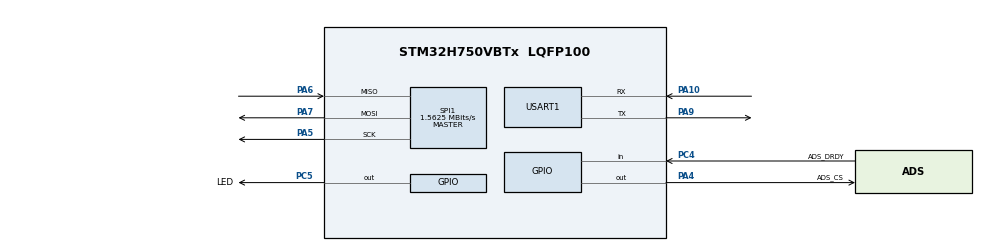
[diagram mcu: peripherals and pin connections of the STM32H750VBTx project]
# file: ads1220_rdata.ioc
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Mcu.Family=STM32H7
Mcu.Name=STM32H750VBTx
Mcu.Package=LQFP100
NVIC.PriorityGroup=NVIC_PRIORITYGROUP_4
NVIC.TIM17_IRQn=true\:15\:0\:false\:false\:true\:false\:true\:true
NVIC.TIM2_IRQn=true\:0\:0\:false\:false\:true\:true\:true\:true
NVIC.TimeBase=TIM17_IRQn
NVIC.TimeBaseIP=TIM17
PA10.Mode=Asynchronous
PA10.Signal=USART1_RX
PA13\ (JTMS/SWDIO).Mode=Serial_Wire
PA13\ (JTMS/SWDIO).Signal=DEBUG_JTMS-SWDIO
PA14\ (JTCK/SWCLK).Mode=Serial_Wire
PA14\ (JTCK/SWCLK).Signal=DEBUG_JTCK-SWCLK
PA4.GPIO_Label=ADS_CS
PA4.GPIO_PuPd=GPIO_PULLUP
PA4.PinState=GPIO_PIN_SET
PA4.Signal=GPIO_Output
PA5.Mode=Full_Duplex_Master
PA5.Signal=SPI1_SCK
PA6.Mode=Full_Duplex_Master
PA6.Signal=SPI1_MISO
PA7.Mode=Full_Duplex_Master
PA7.Signal=SPI1_MOSI
PA9.Mode=Asynchronous
PA9.Signal=USART1_TX
PC4.GPIO_Label=ADS_DRDY
PC4.Signal=GPIO_Input
PC5.GPIO_Label=LED
PC5.Signal=GPIO_Output
PH0-OSC_IN\ (PH0).Mode=HSE-External-Oscillator
PH0-OSC_IN\ (PH0).Signal=RCC_OSC_IN
PH1-OSC_OUT\ (PH1).Mode=HSE-External-Oscillator
PH1-OSC_OUT\ (PH1).Signal=RCC_OSC_OUT
ProjectManager.HeapSize=0x200
ProjectManager.StackSize=0x400
ProjectManager.TargetToolchain=STM32CubeIDE
RCC.ADCFreq_Value=102400000
RCC.APB1Freq_Value=100000000
RCC.APB2Freq_Value=50000000
RCC.APB3Freq_Value=100000000
RCC.APB4Freq_Value=100000000
RCC.CortexFreq_Value=200000000
RCC.D1PPRE=RCC_APB3_DIV2
RCC.D2PPRE1=RCC_APB1_DIV2
RCC.D2PPRE2=RCC_APB2_DIV4
RCC.D3PPRE=RCC_APB4_DIV2
RCC.DIVM1=4
RCC.DIVM2=25
RCC.DIVM3=2
RCC.DIVN1=25
RCC.DIVN2=160
RCC.DIVN3=12
RCC.DIVP2=4
RCC.DIVQ1=4
RCC.DIVQ3=3
RCC.HCLKFreq_Value=200000000
RCC.PLL2FRACN=0
RCC.PLL3FRACN=0
RCC.PLLFRACN=0
RCC.SYSCLKFreq_VALUE=200000000
RCC.SYSCLKSource=RCC_SYSCLKSOURCE_PLLCLK
RCC.USBCLockSelection=RCC_USBCLKSOURCE_PLL3
RCC.USBFreq_Value=128000000
SPI1.BaudRatePrescaler=SPI_BAUDRATEPRESCALER_64
SPI1.CLKPhase=SPI_PHASE_2EDGE
SPI1.CalculateBaudRate=1.5625 MBits/s
SPI1.DataSize=SPI_DATASIZE_8BIT
SPI1.Direction=SPI_DIRECTION_2LINES
SPI1.Mode=SPI_MODE_MASTER
SPI1.VirtualType=VM_MASTER
TIM2.Period=999
TIM2.Prescaler=199
USART1.VirtualMode-Asynchronous=VM_ASYNC
VP_SYS_VS_tim17.Mode=TIM17
VP_TIM2_VS_ClockSourceINT.Mode=Internal
board=custom

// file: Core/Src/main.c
/* USER CODE BEGIN Header */
/**
  ******************************************************************************
  * @file           : main.c
  * @brief          : Main program body
  ******************************************************************************
  * @attention
  *
  * Copyright (c) 2024 STMicroelectronics.
  * All rights reserved.
  *
  * This software is licensed under terms that can be found in the LICENSE file
  * in the root directory of this software component.
  * If no LICENSE file comes with this software, it is provided AS-IS.
  *
  ******************************************************************************
  */
/* USER CODE END Header */
#include "main.h"

/* USER CODE BEGIN Includes */
#include "use.h"
/* USER CODE END Includes */

SPI_HandleTypeDef hspi1;

TIM_HandleTypeDef htim2;

UART_HandleTypeDef huart1;

void SystemClock_Config(void);
static void MX_GPIO_Init(void);
static void MX_SPI1_Init(void);
static void MX_USART1_UART_Init(void);
static void MX_TIM2_Init(void);

/* USER CODE BEGIN 0 */
#ifdef __GNUC__
/* With GCC/RAISONANCE, small printf (option LD Linker->Libraries->Small printf
   set to 'Yes') calls __io_putchar() */
#define PUTCHAR_PROTOTYPE int __io_putchar(int ch)
#else
#define PUTCHAR_PROTOTYPE int fputc(int ch, FILE *f)
#endif /* __GNUC__ */
PUTCHAR_PROTOTYPE
{
  HAL_UART_Transmit(&huart1, (uint8_t *)&ch, 1, 0xFFFF);
  return ch;
}
/* USER CODE END 0 */

int main(void)
{

  /* MCU Configuration--------------------------------------------------------*/

  /* Reset of all peripherals, Initializes the Flash interface and the Systick. */
  HAL_Init();

  /* Configure the system clock */
  SystemClock_Config();

  /* Initialize all configured peripherals */
  MX_GPIO_Init();
  MX_SPI1_Init();
  MX_USART1_UART_Init();
  MX_TIM2_Init();
  /* USER CODE BEGIN 2 */
  setup();
  HAL_TIM_Base_Start_IT(&htim2);
  /* USER CODE END 2 */

  /* Infinite loop */
  while (1)
  {

    /* USER CODE BEGIN 3 */
	  loop();
  }
  /* USER CODE END 3 */
}

void SystemClock_Config(void)
{
  RCC_OscInitTypeDef RCC_OscInitStruct = {0};
  RCC_ClkInitTypeDef RCC_ClkInitStruct = {0};

  /** Supply configuration update enable
  */
  HAL_PWREx_ConfigSupply(PWR_LDO_SUPPLY);

  /** Configure the main internal regulator output voltage
  */
  __HAL_PWR_VOLTAGESCALING_CONFIG(PWR_REGULATOR_VOLTAGE_SCALE3);

  while(!__HAL_PWR_GET_FLAG(PWR_FLAG_VOSRDY)) {}

  /** Initializes the RCC Oscillators according to the specified parameters
  * in the RCC_OscInitTypeDef structure.
  */
  RCC_OscInitStruct.OscillatorType = RCC_OSCILLATORTYPE_HSI;
  RCC_OscInitStruct.HSIState = RCC_HSI_DIV1;
  RCC_OscInitStruct.HSICalibrationValue = RCC_HSICALIBRATION_DEFAULT;
  RCC_OscInitStruct.PLL.PLLState = RCC_PLL_ON;
  RCC_OscInitStruct.PLL.PLLSource = RCC_PLLSOURCE_HSI;
  RCC_OscInitStruct.PLL.PLLM = 4;
  RCC_OscInitStruct.PLL.PLLN = 25;
  RCC_OscInitStruct.PLL.PLLP = 2;
  RCC_OscInitStruct.PLL.PLLQ = 4;
  RCC_OscInitStruct.PLL.PLLR = 2;
  RCC_OscInitStruct.PLL.PLLRGE = RCC_PLL1VCIRANGE_3;
  RCC_OscInitStruct.PLL.PLLVCOSEL = RCC_PLL1VCOWIDE;
  RCC_OscInitStruct.PLL.PLLFRACN = 0;
  if (HAL_RCC_OscConfig(&RCC_OscInitStruct) != HAL_OK)
  {
    Error_Handler();
  }

  /** Initializes the CPU, AHB and APB buses clocks
  */
  RCC_ClkInitStruct.ClockType = RCC_CLOCKTYPE_HCLK|RCC_CLOCKTYPE_SYSCLK
                              |RCC_CLOCKTYPE_PCLK1|RCC_CLOCKTYPE_PCLK2
                              |RCC_CLOCKTYPE_D3PCLK1|RCC_CLOCKTYPE_D1PCLK1;
  RCC_ClkInitStruct.SYSCLKSource = RCC_SYSCLKSOURCE_PLLCLK;
  RCC_ClkInitStruct.SYSCLKDivider = RCC_SYSCLK_DIV1;
  RCC_ClkInitStruct.AHBCLKDivider = RCC_HCLK_DIV1;
  RCC_ClkInitStruct.APB3CLKDivider = RCC_APB3_DIV2;
  RCC_ClkInitStruct.APB1CLKDivider = RCC_APB1_DIV2;
  RCC_ClkInitStruct.APB2CLKDivider = RCC_APB2_DIV4;
  RCC_ClkInitStruct.APB4CLKDivider = RCC_APB4_DIV2;

  if (HAL_RCC_ClockConfig(&RCC_ClkInitStruct, FLASH_LATENCY_4) != HAL_OK)
  {
    Error_Handler();
  }
}

static void MX_SPI1_Init(void)
{

  /* SPI1 parameter configuration*/
  hspi1.Instance = SPI1;
  hspi1.Init.Mode = SPI_MODE_MASTER;
  hspi1.Init.Direction = SPI_DIRECTION_2LINES;
  hspi1.Init.DataSize = SPI_DATASIZE_8BIT;
  hspi1.Init.CLKPolarity = SPI_POLARITY_LOW;
  hspi1.Init.CLKPhase = SPI_PHASE_2EDGE;
  hspi1.Init.NSS = SPI_NSS_SOFT;
  hspi1.Init.BaudRatePrescaler = SPI_BAUDRATEPRESCALER_64;
  hspi1.Init.FirstBit = SPI_FIRSTBIT_MSB;
  hspi1.Init.TIMode = SPI_TIMODE_DISABLE;
  hspi1.Init.CRCCalculation = SPI_CRCCALCULATION_DISABLE;
  hspi1.Init.CRCPolynomial = 0x0;
  hspi1.Init.NSSPMode = SPI_NSS_PULSE_ENABLE;
  hspi1.Init.NSSPolarity = SPI_NSS_POLARITY_LOW;
  hspi1.Init.FifoThreshold = SPI_FIFO_THRESHOLD_01DATA;
  hspi1.Init.TxCRCInitializationPattern = SPI_CRC_INITIALIZATION_ALL_ZERO_PATTERN;
  hspi1.Init.RxCRCInitializationPattern = SPI_CRC_INITIALIZATION_ALL_ZERO_PATTERN;
  hspi1.Init.MasterSSIdleness = SPI_MASTER_SS_IDLENESS_00CYCLE;
  hspi1.Init.MasterInterDataIdleness = SPI_MASTER_INTERDATA_IDLENESS_00CYCLE;
  hspi1.Init.MasterReceiverAutoSusp = SPI_MASTER_RX_AUTOSUSP_DISABLE;
  hspi1.Init.MasterKeepIOState = SPI_MASTER_KEEP_IO_STATE_DISABLE;
  hspi1.Init.IOSwap = SPI_IO_SWAP_DISABLE;
  if (HAL_SPI_Init(&hspi1) != HAL_OK)
  {
    Error_Handler();
  }

}

static void MX_TIM2_Init(void)
{

  TIM_ClockConfigTypeDef sClockSourceConfig = {0};
  TIM_MasterConfigTypeDef sMasterConfig = {0};

  htim2.Instance = TIM2;
  htim2.Init.Prescaler = 199;
  htim2.Init.CounterMode = TIM_COUNTERMODE_UP;
  htim2.Init.Period = 999;
  htim2.Init.ClockDivision = TIM_CLOCKDIVISION_DIV1;
  htim2.Init.AutoReloadPreload = TIM_AUTORELOAD_PRELOAD_DISABLE;
  if (HAL_TIM_Base_Init(&htim2) != HAL_OK)
  {
    Error_Handler();
  }
  sClockSourceConfig.ClockSource = TIM_CLOCKSOURCE_INTERNAL;
  if (HAL_TIM_ConfigClockSource(&htim2, &sClockSourceConfig) != HAL_OK)
  {
    Error_Handler();
  }
  sMasterConfig.MasterOutputTrigger = TIM_TRGO_RESET;
  sMasterConfig.MasterSlaveMode = TIM_MASTERSLAVEMODE_DISABLE;
  if (HAL_TIMEx_MasterConfigSynchronization(&htim2, &sMasterConfig) != HAL_OK)
  {
    Error_Handler();
  }

}

static void MX_USART1_UART_Init(void)
{

  huart1.Instance = USART1;
  huart1.Init.BaudRate = 115200;
  huart1.Init.WordLength = UART_WORDLENGTH_8B;
  huart1.Init.StopBits = UART_STOPBITS_1;
  huart1.Init.Parity = UART_PARITY_NONE;
  huart1.Init.Mode = UART_MODE_TX_RX;
  huart1.Init.HwFlowCtl = UART_HWCONTROL_NONE;
  huart1.Init.OverSampling = UART_OVERSAMPLING_16;
  huart1.Init.OneBitSampling = UART_ONE_BIT_SAMPLE_DISABLE;
  huart1.Init.ClockPrescaler = UART_PRESCALER_DIV1;
  huart1.AdvancedInit.AdvFeatureInit = UART_ADVFEATURE_NO_INIT;
  if (HAL_UART_Init(&huart1) != HAL_OK)
  {
    Error_Handler();
  }
  if (HAL_UARTEx_SetTxFifoThreshold(&huart1, UART_TXFIFO_THRESHOLD_1_8) != HAL_OK)
  {
    Error_Handler();
  }
  if (HAL_UARTEx_SetRxFifoThreshold(&huart1, UART_RXFIFO_THRESHOLD_1_8) != HAL_OK)
  {
    Error_Handler();
  }
  if (HAL_UARTEx_DisableFifoMode(&huart1) != HAL_OK)
  {
    Error_Handler();
  }

}

static void MX_GPIO_Init(void)
{
  GPIO_InitTypeDef GPIO_InitStruct = {0};

  /* GPIO Ports Clock Enable */
  __HAL_RCC_GPIOH_CLK_ENABLE();
  __HAL_RCC_GPIOA_CLK_ENABLE();
  __HAL_RCC_GPIOC_CLK_ENABLE();

  /*Configure GPIO pin Output Level */
  HAL_GPIO_WritePin(ADS_CS_GPIO_Port, ADS_CS_Pin, GPIO_PIN_SET);

  /*Configure GPIO pin Output Level */
  HAL_GPIO_WritePin(LED_GPIO_Port, LED_Pin, GPIO_PIN_RESET);

  /*Configure GPIO pin : ADS_CS_Pin */
  GPIO_InitStruct.Pin = ADS_CS_Pin;
  GPIO_InitStruct.Mode = GPIO_MODE_OUTPUT_PP;
  GPIO_InitStruct.Pull = GPIO_PULLUP;
  GPIO_InitStruct.Speed = GPIO_SPEED_FREQ_LOW;
  HAL_GPIO_Init(ADS_CS_GPIO_Port, &GPIO_InitStruct);

  /*Configure GPIO pin : ADS_DRDY_Pin */
  GPIO_InitStruct.Pin = ADS_DRDY_Pin;
  GPIO_InitStruct.Mode = GPIO_MODE_INPUT;
  GPIO_InitStruct.Pull = GPIO_NOPULL;
  HAL_GPIO_Init(ADS_DRDY_GPIO_Port, &GPIO_InitStruct);

  /*Configure GPIO pin : LED_Pin */
  GPIO_InitStruct.Pin = LED_Pin;
  GPIO_InitStruct.Mode = GPIO_MODE_OUTPUT_PP;
  GPIO_InitStruct.Pull = GPIO_NOPULL;
  GPIO_InitStruct.Speed = GPIO_SPEED_FREQ_LOW;
  HAL_GPIO_Init(LED_GPIO_Port, &GPIO_InitStruct);

}

void HAL_TIM_PeriodElapsedCallback(TIM_HandleTypeDef *htim)
{
  /* USER CODE BEGIN Callback 0 */
	  if (htim->Instance == TIM2) {
	    tim_callback();
	  }
  /* USER CODE END Callback 0 */
  if (htim->Instance == TIM17) {
    HAL_IncTick();
  }
}

void Error_Handler(void)
{
  __disable_irq();
  while (1)
  {
  }
}
